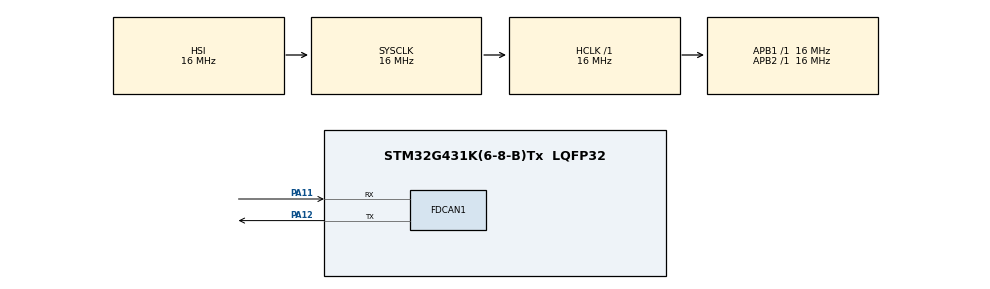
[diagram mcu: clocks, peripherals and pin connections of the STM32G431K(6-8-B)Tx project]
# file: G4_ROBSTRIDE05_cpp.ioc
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FDCAN1.CalculateBaudRateNominal=1000000
FDCAN1.CalculateTimeBitNominal=1000
FDCAN1.CalculateTimeQuantumNominal=125.0
FDCAN1.ExtFiltersNbr=1
FDCAN1.NominalPrescaler=2
FDCAN1.NominalTimeSeg1=4
FDCAN1.NominalTimeSeg2=3
Mcu.Family=STM32G4
Mcu.Name=STM32G431K(6-8-B)Tx
Mcu.Package=LQFP32
NVIC.FDCAN1_IT0_IRQn=true\:0\:0\:false\:false\:true\:true\:true\:true
NVIC.PriorityGroup=NVIC_PRIORITYGROUP_4
PA11.Mode=FDCAN_Activate
PA11.Signal=FDCAN1_RX
PA12.Mode=FDCAN_Activate
PA12.Signal=FDCAN1_TX
ProjectManager.HeapSize=0x200
ProjectManager.StackSize=0x400
ProjectManager.TargetToolchain=STM32CubeIDE
RCC.AHBFreq_Value=16000000
RCC.APB1Freq_Value=16000000
RCC.APB1TimFreq_Value=16000000
RCC.APB2Freq_Value=16000000
RCC.APB2TimFreq_Value=16000000
RCC.CortexFreq_Value=16000000
RCC.EXTERNAL_CLOCK_VALUE=12288000
RCC.HCLKFreq_Value=16000000
RCC.HSE_VALUE=8000000
RCC.HSI48_VALUE=48000000
RCC.HSI_VALUE=16000000
RCC.LSE_VALUE=32768
RCC.SYSCLKFreq_VALUE=16000000
RCC.USBFreq_Value=64000000
RCC.VCOOutputFreq_Value=128000000
VP_SYS_VS_DBSignals.Mode=DisableDeadBatterySignals
board=custom

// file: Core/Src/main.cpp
/* USER CODE BEGIN Header */
/**
  ******************************************************************************
  * @file           : main.c
  * @brief          : Main program body
  ******************************************************************************
  * @attention
  *
  * Copyright (c) 2025 STMicroelectronics.
  * All rights reserved.
  *
  * This software is licensed under terms that can be found in the LICENSE file
  * in the root directory of this software component.
  * If no LICENSE file comes with this software, it is provided AS-IS.
  *
  ******************************************************************************
  */
/* USER CODE END Header */
#include "main.h"

/* USER CODE BEGIN Includes */
#include "Robstride.h"
/* USER CODE END Includes */

FDCAN_HandleTypeDef hfdcan1;

/* USER CODE BEGIN PV */
FDCAN_TxHeaderTypeDef TxHeader;
uint8_t TxData[8];
uint8_t RxData[8];

RobStride_Motor RobStride_01(0x7F, false);
uint8_t mode = 2;
int cnt;
uint8_t torque = 5;
uint8_t angle;
uint8_t speed;

/* USER CODE END PV */

void SystemClock_Config(void);
static void MX_GPIO_Init(void);
static void MX_FDCAN1_Init(void);
/* USER CODE BEGIN PFP */
static void FDCAN1_Config(void){
	FDCAN_FilterTypeDef sFilterConfig;

	sFilterConfig.IdType = FDCAN_EXTENDED_ID;
	sFilterConfig.FilterIndex = 0;
	sFilterConfig.FilterType = FDCAN_FILTER_MASK;
	sFilterConfig.FilterConfig = FDCAN_FILTER_TO_RXFIFO0;
	sFilterConfig.FilterID1 = 0x000;
	sFilterConfig.FilterID2 = 0x000;
	if(HAL_FDCAN_ConfigFilter(&hfdcan1, &sFilterConfig) != HAL_OK){
		Error_Handler();
	}
	/* Configure global filter to reject all non-matching frames */
	if(HAL_FDCAN_ConfigGlobalFilter(&hfdcan1, FDCAN_REJECT, FDCAN_REJECT, FDCAN_REJECT_REMOTE, FDCAN_REJECT_REMOTE) != HAL_OK){
		Error_Handler();
	}
	if(HAL_FDCAN_Start(&hfdcan1) != HAL_OK){
		Error_Handler();
	}
	if(HAL_FDCAN_ActivateNotification(&hfdcan1, FDCAN_IT_RX_FIFO0_NEW_MESSAGE, 0) != HAL_OK){
		Error_Handler();
	}

	TxHeader.Identifier = 0x1200FD01;
	TxHeader.IdType = FDCAN_EXTENDED_ID;
	TxHeader.TxFrameType = FDCAN_DATA_FRAME;
	TxHeader.DataLength = 8;
	TxHeader.ErrorStateIndicator = FDCAN_ESI_ACTIVE;
	TxHeader.BitRateSwitch = FDCAN_BRS_OFF;
	TxHeader.FDFormat = FDCAN_CLASSIC_CAN;
	TxHeader.TxEventFifoControl = FDCAN_NO_TX_EVENTS;
	TxHeader.MessageMarker = 0;
}

void HAL_FDCAN_RxFifo0Callback(FDCAN_HandleTypeDef *hfdcan, uint32_t RxFifo0ITs){
	FDCAN_RxHeaderTypeDef RxHeader;

	if((RxFifo0ITs & FDCAN_IT_RX_FIFO0_NEW_MESSAGE) != RESET){
		if(HAL_FDCAN_GetRxMessage(hfdcan, FDCAN_RX_FIFO0, &RxHeader, RxData) != HAL_OK){
			Error_Handler();
		}
	}
}
/* USER CODE END PFP */

int main(void)
{

  /* MCU Configuration--------------------------------------------------------*/

  /* Reset of all peripherals, Initializes the Flash interface and the Systick. */
  HAL_Init();

  /* Configure the system clock */
  SystemClock_Config();

  /* Initialize all configured peripherals */
  MX_GPIO_Init();
  MX_FDCAN1_Init();
  /* USER CODE BEGIN 2 */
  FDCAN1_Config();
  /* USER CODE END 2 */

  /* Infinite loop */
  /* USER CODE BEGIN WHILE */
  while (1)
  {
	  switch(mode)
	  	      {
	  	          // ===== 普通模式接口 =====
	  	          case 0: // 使能（普通模式）
	  	              RobStride_01.Enable_Motor();
	  	              break;
	  	          case 1: // 失能（普通模式）
	  	              RobStride_01.Disenable_Motor(1);
	  	              break;
	  	          case 2: // 运控模式
	  	              HAL_Delay(5);
	  	              RobStride_01.RobStride_Motor_move_control(torque, 0, 0, 0.0, 0.0);
	  	              break;
	  	          case 3: // PP位置模式
	  	              RobStride_01.RobStride_Motor_Pos_control(2.0, 2);
	  	  						HAL_Delay(5);
	  	              break;
	  	  				case 4:	//CSP位置模式
	  	  						RobStride_01.RobStride_Motor_CSP_control(2.0, 2.0);
	  	  						HAL_Delay(5);
	  	  						break;
	  	          case 5: // 速度模式
	  	              RobStride_01.RobStride_Motor_Speed_control(3.5, 5.0);
	  	  						HAL_Delay(5);
	  	              break;
	  	          case 6: // 电流模式
	  	              HAL_Delay(5);
	  	              RobStride_01.RobStride_Motor_current_control(1.2);
	  	              break;
	  	          case 7: // 设置机械零点
	  	              RobStride_01.Set_ZeroPos();
	  	              break;
	  	          case 8: // 读取参数
	  	              RobStride_01.Get_RobStride_Motor_parameter(0x7014);
	  	              break;
	  	          case 9: // 设置参数
	  	              RobStride_01.Set_RobStride_Motor_parameter(0x7014, 0.35f, Set_parameter);
	  	              break;
	  	          case 10: // 协议切换（如切MIT协议/Canopen/私有协议）
	  	              RobStride_01.RobStride_Motor_MotorModeSet(0x02); // 0x02=MIT
	  	              break;

	  	          // ===== MIT模式接口（只能用MIT专用函数！） =====
	  	          case 11: // MIT 使能
	  	              RobStride_01.RobStride_Motor_MIT_Enable();
	  	              break;
	  	          case 12: // MIT 失能
	  	              RobStride_01.RobStride_Motor_MIT_Disable();
	  	              break;
	  	          case 13: // MIT 综合控制
	  	  						RobStride_01.RobStride_Motor_MIT_SetMotorType(0x01);
	  	              RobStride_01.RobStride_Motor_MIT_Enable();
	  	              HAL_Delay(5);
	  	              RobStride_01.RobStride_Motor_MIT_Control(0, 0, 0, 0, -1.0f);
	  	              break;
	  	          case 14: // MIT 位置控制
	  	  						RobStride_01.RobStride_Motor_MIT_SetMotorType(0x01);
	  	  						RobStride_01.RobStride_Motor_MIT_Enable();
	  	              HAL_Delay(5);
	  	              RobStride_01.RobStride_Motor_MIT_PositionControl(1.57f, 3.0f);
	  	              break;
	  	          case 15: // MIT 速度控制
	  	  						RobStride_01.RobStride_Motor_MIT_SetMotorType(0x02);
	  	  						RobStride_01.RobStride_Motor_MIT_Enable();
	  	              HAL_Delay(5);
	  	              RobStride_01.RobStride_Motor_MIT_SpeedControl(4.5f, 3.2f);
	  	              break;
	  	          case 16: // MIT 零点设置（运行前需保证 MIT_Type != positionControl）
	  	              RobStride_01.RobStride_Motor_MIT_SetZeroPos();
	  	              break;
	  	          case 17: // MIT 清错
	  	              RobStride_01.RobStride_Motor_MIT_ClearOrCheckError(0x01);
	  	              break;
	  	          case 18: // MIT 设置电机运行模式
	  	              RobStride_01.RobStride_Motor_MIT_SetMotorType(0x01);
	  	              break;
	  	          case 19: // MIT 设置电机ID
	  	              RobStride_01.RobStride_Motor_MIT_SetMotorId(0x05);
	  	              break;
	  	          case 20: //主动上报
	  	              RobStride_01.RobStride_Motor_ProactiveEscalationSet(0x00);
	  	              break;
	  	          case 21: // 波特率修改
	  	              RobStride_01.RobStride_Motor_BaudRateChange(0x01);
	  	              break;
	  	          case 22: // MIT 参数保存
	  	              RobStride_01.RobStride_Motor_MotorDataSave();
	  	              break;
	  	  				case 23: // MIT 协议切换（如切MIT协议/Canopen/私有协议）
	  	  						RobStride_01.RobStride_Motor_MIT_MotorModeSet(0x00);
	  	  						break;

	  	          default:
	  	              break;
	  	      }
//	  	  cnt++;
//	  	  if(cnt<100){
//	  		  mode = 2;
//	  	  }else if(cnt < 200){
//	  		  torque = 5;
//	  	  }else if(cnt < 300){
//	  		  torque = 0;
//	  	  }else if(cnt < 400){
//	  		  cnt = 0;
//	  	  }
	  	  		HAL_Delay(50);
    /* USER CODE END WHILE */

  }
}

void SystemClock_Config(void)
{
  RCC_OscInitTypeDef RCC_OscInitStruct = {0};
  RCC_ClkInitTypeDef RCC_ClkInitStruct = {0};

  /** Configure the main internal regulator output voltage
  */
  HAL_PWREx_ControlVoltageScaling(PWR_REGULATOR_VOLTAGE_SCALE1);

  /** Initializes the RCC Oscillators according to the specified parameters
  * in the RCC_OscInitTypeDef structure.
  */
  RCC_OscInitStruct.OscillatorType = RCC_OSCILLATORTYPE_HSI;
  RCC_OscInitStruct.HSIState = RCC_HSI_ON;
  RCC_OscInitStruct.HSICalibrationValue = RCC_HSICALIBRATION_DEFAULT;
  RCC_OscInitStruct.PLL.PLLState = RCC_PLL_NONE;
  if (HAL_RCC_OscConfig(&RCC_OscInitStruct) != HAL_OK)
  {
    Error_Handler();
  }

  /** Initializes the CPU, AHB and APB buses clocks
  */
  RCC_ClkInitStruct.ClockType = RCC_CLOCKTYPE_HCLK|RCC_CLOCKTYPE_SYSCLK
                              |RCC_CLOCKTYPE_PCLK1|RCC_CLOCKTYPE_PCLK2;
  RCC_ClkInitStruct.SYSCLKSource = RCC_SYSCLKSOURCE_HSI;
  RCC_ClkInitStruct.AHBCLKDivider = RCC_SYSCLK_DIV1;
  RCC_ClkInitStruct.APB1CLKDivider = RCC_HCLK_DIV1;
  RCC_ClkInitStruct.APB2CLKDivider = RCC_HCLK_DIV1;

  if (HAL_RCC_ClockConfig(&RCC_ClkInitStruct, FLASH_LATENCY_0) != HAL_OK)
  {
    Error_Handler();
  }
}

static void MX_FDCAN1_Init(void)
{

  hfdcan1.Instance = FDCAN1;
  hfdcan1.Init.ClockDivider = FDCAN_CLOCK_DIV1;
  hfdcan1.Init.FrameFormat = FDCAN_FRAME_CLASSIC;
  hfdcan1.Init.Mode = FDCAN_MODE_NORMAL;
  hfdcan1.Init.AutoRetransmission = DISABLE;
  hfdcan1.Init.TransmitPause = DISABLE;
  hfdcan1.Init.ProtocolException = DISABLE;
  hfdcan1.Init.NominalPrescaler = 2;
  hfdcan1.Init.NominalSyncJumpWidth = 1;
  hfdcan1.Init.NominalTimeSeg1 = 4;
  hfdcan1.Init.NominalTimeSeg2 = 3;
  hfdcan1.Init.DataPrescaler = 1;
  hfdcan1.Init.DataSyncJumpWidth = 1;
  hfdcan1.Init.DataTimeSeg1 = 1;
  hfdcan1.Init.DataTimeSeg2 = 1;
  hfdcan1.Init.StdFiltersNbr = 0;
  hfdcan1.Init.ExtFiltersNbr = 1;
  hfdcan1.Init.TxFifoQueueMode = FDCAN_TX_FIFO_OPERATION;
  if (HAL_FDCAN_Init(&hfdcan1) != HAL_OK)
  {
    Error_Handler();
  }

}

static void MX_GPIO_Init(void)
{

  /* GPIO Ports Clock Enable */
  __HAL_RCC_GPIOA_CLK_ENABLE();

}

void Error_Handler(void)
{
  __disable_irq();
  while (1)
  {
  }
}
